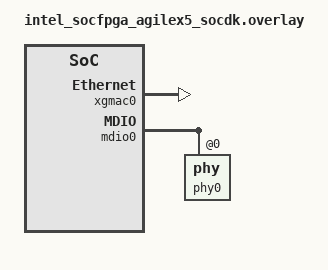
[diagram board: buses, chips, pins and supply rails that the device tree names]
/*
 * Copyright (C) 2023 Intel Corporation
 * SPDX-License-Identifier: Apache-2.0
 */

/* The overlay file should be used to enable any
 * dts nodes required by this application for this
 * board.
 */

&xgmac0 {
	status = "okay";

	phc0: phc@0 {
		status = "okay";
	};
};

&mdio0  {
	status = "okay";

	phy0: phy@0 {
		status = "okay";
	};
};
